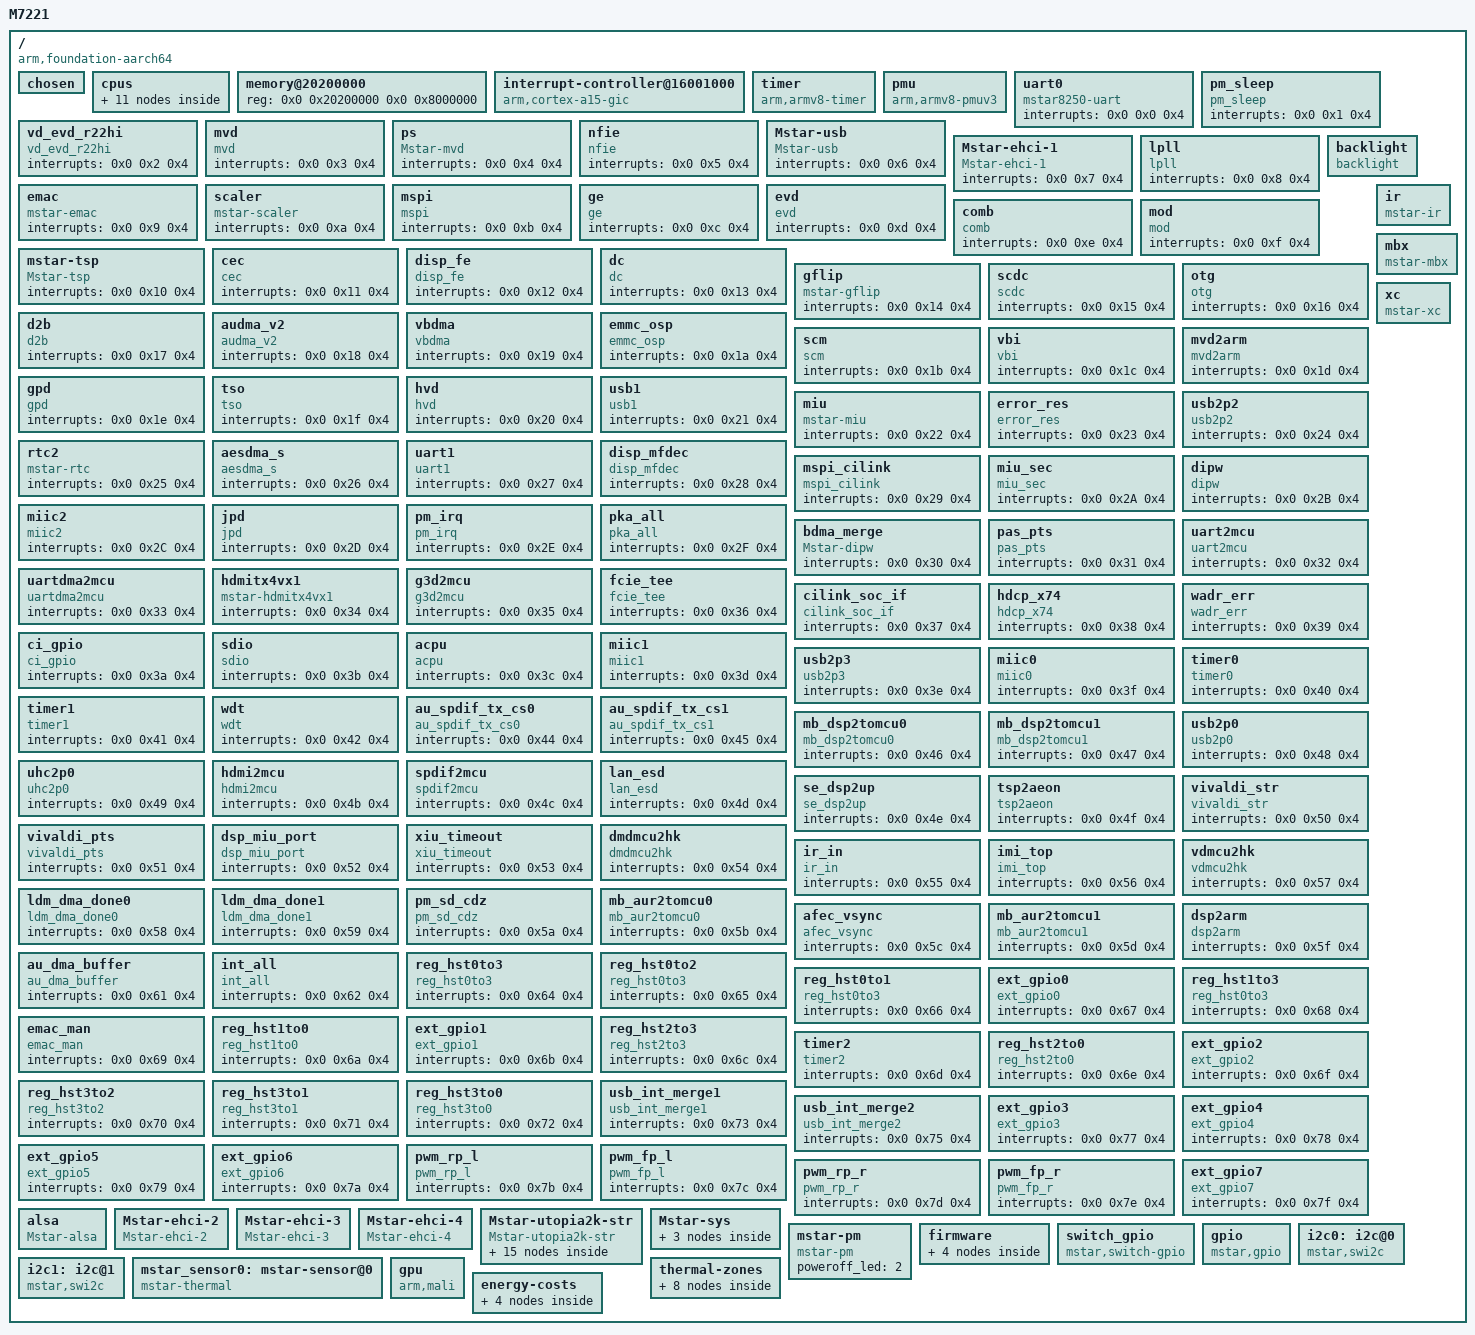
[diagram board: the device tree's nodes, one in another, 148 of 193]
#include <dt-bindings/interrupt-controller/arm-gic.h>
#include <dt-bindings/interrupt-controller/irq.h>
#include <dt-bindings/thermal/thermal.h>

/dts-v1/;

/ {
	model = "M7221";
	compatible = "arm,foundation-aarch64", "arm,m7221";
	interrupt-parent = <0x1>;
	#address-cells = <0x2>;
	#size-cells = <0x2>;

	chosen {
		bootargs = "console=ttyS0,115200 androidboot.console=ttyS0 root=/dev/ram rw rootwait init=/init CORE_DUMP_PATH=/data/core_dump.%%p.gz KDebug=1 delaylogo=true androidboot.selinux=permissive LX_MEM=0x3D500000 LX_MEM2=0xC0000000,0x1FF00000 EMAC_MEM=0x100000 PM51_ADDR=0x20010000 PM51_LEN=0x10000 CMA0=OTHERS,miu=0,hid=23,sz=0x7000000,st=0x11000000 CMA1=VDEC0,miu=0,hid=20,sz=0x3000000,st=0x18000000 CMA2=XC0,miu=0,hid=22,sz=0x6000000,st=0x1b000000 CMA3=OTHERS2,miu=1,hid=24,sz=0xec00000,st=0x0 CMA4=VDEC1,miu=1,hid=19,sz=0x7000000,st=0xec00000 CMA5=RETURN_ENUM,miu=1,hid=25,sz=0x2400000,st=0x15c00000 BOOTLOGO_IN_MBOOT ENV_VAR_OFFSET=0x0 ENV_VAR_SIZE=0x10000 ENV=EMMC SECURITY=ON";
	};

	cpus {
		#address-cells = <0x2>;
		#size-cells = <0x0>;

		cpu-map {

			cluster0: cluster0 {
				#cooling-cells = <0x2>;

				core0 {
					cpu = <0x2>;
				};
                                
				core1 {
					cpu = <0x3>;
				};
			};
                        
			cluster1: cluster1 {
				#cooling-cells = <0x2>;

				core0 {
					cpu = <0x4>;
				};

				core1 {
					cpu = <0x5>;
				};
			};
                       
		};

		cpu0: cpu@0 {
			compatible = "arm,cortex-a53", "arm,armv8";
			reg = <0x0 0x0>;
			device_type = "cpu";
			enable-method = "mstar-spin-table";
			cpu-release-addr = <0x0 0x100510>;
			linux,phandle = <0x2>;
			phandle = <0x2>;
			sched-energy-costs = <&CPU_COST_1 &CLUSTER_COST_1>;
		};

		cpu1: cpu@1 {
			compatible = "arm,cortex-a53", "arm,armv8";
			reg = <0x0 0x1>;
			device_type = "cpu";
			enable-method = "mstar-spin-table";
			cpu-release-addr = <0x0 0x100510>;
			linux,phandle = <0x3>;
			phandle = <0x3>;
			sched-energy-costs = <&CPU_COST_1 &CLUSTER_COST_1>;
		};

		cpu2: cpu@100 {
			compatible = "arm,cortex-a73", "arm,armv8";
			reg = <0x0 0x100>;
			device_type = "cpu";
			enable-method = "mstar-spin-table";
			cpu-release-addr = <0x0 0x100510>;
			linux,phandle = <0x4>;
			phandle = <0x4>;
			sched-energy-costs = <&CPU_COST_0 &CLUSTER_COST_0>;
		};

		cpu3: cpu@101 {
			compatible = "arm,cortex-a73", "arm,armv8";
			reg = <0x0 0x101>;
			device_type = "cpu";
			enable-method = "mstar-spin-table";
			cpu-release-addr = <0x0 0x100510>;
			linux,phandle = <0x5>;
			phandle = <0x5>;
			sched-energy-costs = <&CPU_COST_0 &CLUSTER_COST_0>;
		};
	};

	memory@20200000 {
		device_type = "memory";
		reg = <0x0 0x20200000 0x0 0x8000000>;
	};

	interrupt-controller@16001000 {
		compatible = "arm,cortex-a15-gic", "arm,cortex-a9-gic";
		#interrupt-cells = <0x3>;
		#address-cells = <0x0>;
		interrupt-controller;
		reg = <0x0 0x16001000 0x0 0x1000 0x0 0x16002000 0x0 0x4000>;
		interrupts = <0x1 0x9 0xf04>;
		linux,phandle = <0x1>;
		phandle = <0x1>;
	};

	timer {
		compatible = "arm,armv8-timer";
		interrupts = <0x1 0xd 0xff01 0x1 0xe 0xff01 0x1 0xb 0xff01 0x1 0xa 0xff01>;
		clock-frequency = <0xb71b00>;
	};

	pmu {
		compatible = "arm,armv8-pmuv3";
		interrupts = <0x0 142 0x4>,<0x0 143 0x4>,<0x0 146 0x4>,<0x0 147 0x4>;
		interrupt-affinity = <&cpu0>,<&cpu1>,<&cpu2>,<&cpu3>;
	};

	uart0 {
		compatible = "mstar8250-uart";
		interrupts = <0x0 0x0 0x4>;
	};

	pm_sleep {
		compatible = "pm_sleep";
		interrupts = <0x0 0x1 0x4>;
	};

	vd_evd_r22hi {
		compatible = "vd_evd_r22hi";
		interrupts = <0x0 0x2 0x4>;
	};

	mvd {
		compatible = "mvd";
		interrupts = <0x0 0x3 0x4>;
	};

	ps {
		compatible = "Mstar-mvd";
		interrupts = <0x0 0x4 0x4>;
	};

	nfie {
		compatible = "nfie";
		interrupts = <0x0 0x5 0x4>;
	};

	Mstar-usb {
		compatible = "Mstar-usb";
		interrupts = <0x0 0x6 0x4>;
	};

	Mstar-ehci-1 {
		compatible = "Mstar-ehci-1";
		interrupts = <0x0 0x7 0x4>;
	};

	lpll {
		compatible = "lpll";
		interrupts = <0x0 0x8 0x4>;
	};

	emac {
		compatible = "mstar-emac";
		interrupts = <0x0 0x9 0x4>;
	};

	scaler {
		compatible = "mstar-scaler";
		interrupts = <0x0 0xa 0x4>;
	};

	mspi {
		compatible = "mspi";
		interrupts = <0x0 0xb 0x4>;
	};

	ge {
		compatible = "ge";
		interrupts = <0x0 0xc 0x4>;
	};

	evd   {
		compatible = "evd";
		interrupts = <0x0 0xd 0x4>;
	};

	comb {
		compatible = "comb";
		interrupts = <0x0 0xe 0x4>;
	};

	mod {
		compatible = "mod";
		interrupts = <0x0 0xf 0x4>;
	};

	mstar-tsp {
		compatible = "Mstar-tsp";
		interrupts = <0x0 0x10 0x4>;
	};

	cec {
		compatible = "cec";
		interrupts = <0x0 0x11 0x4>;
	};

	disp_fe {
		compatible = "disp_fe";
		interrupts = <0x0 0x12 0x4>;
	};

	dc {
		compatible = "dc";
		interrupts = <0x0 0x13 0x4>;
	};

    backlight {
        compatible = "backlight";
        brightness-levels = <0 255>;
        default-brightness-level = <1>;
        bl_ctrl = <5>;
    };

	gflip {
		compatible = "mstar-gflip";
		interrupts = <0x0 0x14 0x4>;
	};

	scdc {
		compatible = "scdc";
		interrupts = <0x0 0x15 0x4>;
	};

	otg {
		compatible = "otg";
		interrupts = <0x0 0x16 0x4>;
	};

	d2b {
		compatible = "d2b";
		interrupts = <0x0 0x17 0x4>;
	};

	audma_v2 {
		compatible = "audma_v2";
		interrupts = <0x0 0x18 0x4>;
	};

	vbdma {
		compatible = "vbdma";
		interrupts = <0x0 0x19 0x4>;
	};

	emmc_osp {
		compatible = "emmc_osp";
		interrupts = <0x0 0x1a 0x4>;
	};

	scm {
		compatible = "scm";
		interrupts = <0x0 0x1b 0x4>;
	};

	vbi {
		compatible = "vbi";
		interrupts = <0x0 0x1c 0x4>;
	};

	mvd2arm {
		compatible = "mvd2arm";
		interrupts = <0x0 0x1d 0x4>;
	};

	gpd {
		compatible = "gpd";
		interrupts = <0x0 0x1e 0x4>;
	};

	tso {
		compatible = "tso";
		interrupts = <0x0 0x1f 0x4>;
	};

	hvd {
		compatible = "hvd";
		interrupts = <0x0 0x20 0x4>;
	};

	usb1 {
		compatible = "usb1";
		interrupts = <0x0 0x21 0x4>;
	};

	miu {
		compatible = "mstar-miu";
		interrupts = <0x0 0x22 0x4>;
	};

	error_res {
		compatible = "error_res";
		interrupts = <0x0 0x23 0x4>;
	};

	usb2p2 {
		compatible = "usb2p2";
		interrupts = <0x0 0x24 0x4>;
	};

	rtc2 {
		compatible = "mstar-rtc";
		interrupts = <0x0 0x25 0x4>;
	};

	aesdma_s {
		compatible = "aesdma_s";
		interrupts = <0x0 0x26 0x4>;
	};

	uart1 {
		compatible = "uart1";
		interrupts = <0x0 0x27 0x4>;
	};

	disp_mfdec {
		compatible = "disp_mfdec";
		interrupts = <0x0 0x28 0x4>;
	};

	mspi_cilink {
		compatible = "mspi_cilink";
		interrupts = <0x0 0x29 0x4>;
	};

	miu_sec {
		compatible = "miu_sec";
		interrupts = <0x0 0x2A 0x4>;
	};

	dipw {
		compatible = "dipw";
		interrupts = <0x0 0x2B 0x4>;
	};

	miic2 {
		compatible = "miic2";
		interrupts = <0x0 0x2C 0x4>;
	};

	jpd {
		compatible = "jpd";
		interrupts = <0x0 0x2D 0x4>;
	};

	pm_irq {
		compatible = "pm_irq";
		interrupts = <0x0 0x2E 0x4>;
	};

	pka_all {
		compatible = "pka_all";
		interrupts = <0x0 0x2F 0x4>;
	};

	bdma_merge {
		compatible = "Mstar-dipw";
		interrupts = <0x0 0x30 0x4>;
	};

	pas_pts {
		compatible = "pas_pts";
		interrupts = <0x0 0x31 0x4>;
	};

	uart2mcu {
		compatible = "uart2mcu";
		interrupts = <0x0 0x32 0x4>;
	};

	uartdma2mcu {
		compatible = "uartdma2mcu";
		interrupts = <0x0 0x33 0x4>;
	};

	hdmitx4vx1 {
		compatible = "mstar-hdmitx4vx1";
		interrupts = <0x0 0x34 0x4>;
	};

	g3d2mcu {
		compatible = "g3d2mcu";
		interrupts = <0x0 0x35 0x4>;
	};

	fcie_tee {
		compatible = "fcie_tee";
		interrupts = <0x0 0x36 0x4>;
	};

	cilink_soc_if {
		compatible = "cilink_soc_if";
		interrupts = <0x0 0x37 0x4>;
	};

	hdcp_x74 {
		compatible = "hdcp_x74 ";
		interrupts = <0x0 0x38 0x4>;
	};

	wadr_err {
		compatible = "wadr_err";
		interrupts = <0x0 0x39 0x4>;
	};

	ci_gpio {
		compatible = "ci_gpio";
		interrupts = <0x0 0x3a 0x4>;
	};

	sdio {
		compatible = "sdio";
		interrupts = <0x0 0x3b 0x4>;
	};

	acpu {
		compatible = "acpu";
		interrupts = <0x0 0x3c 0x4>;
	};

	miic1 {
		compatible = "miic1";
		interrupts = <0x0 0x3d 0x4>;
	};

	usb2p3 {
		compatible = "usb2p3";
		interrupts = <0x0 0x3e 0x4>;
	};

	miic0 {
		compatible = "miic0";
		interrupts = <0x0 0x3f 0x4>;
	};

	timer0{
		compatible = "timer0";
		interrupts = <0x0 0x40 0x4>;
	};

	timer1{
		compatible = "timer1";
		interrupts = <0x0 0x41 0x4>;
	};

	wdt {
		compatible = "wdt";
		interrupts = <0x0 0x42 0x4>;
	};

	au_spdif_tx_cs0 {
		compatible = "au_spdif_tx_cs0";
		interrupts = <0x0 0x44 0x4>;
	};

	au_spdif_tx_cs1 {
		compatible = "au_spdif_tx_cs1";
		interrupts = <0x0 0x45 0x4>;
	};

	mb_dsp2tomcu0 {
		compatible = "mb_dsp2tomcu0";
		interrupts = <0x0 0x46 0x4>;
	};

	mb_dsp2tomcu1 {
		compatible = "mb_dsp2tomcu1";
		interrupts = <0x0 0x47 0x4>;
	};

	usb2p0 {
		compatible = "usb2p0";
		interrupts = <0x0 0x48 0x4>;
	};

	uhc2p0 {
		compatible = "uhc2p0";
		interrupts = <0x0 0x49 0x4>;
	};

	hdmi2mcu {
		compatible = "hdmi2mcu";
		interrupts = <0x0 0x4b 0x4>;
	};

	spdif2mcu {
		compatible = "spdif2mcu";
		interrupts = <0x0 0x4c 0x4>;
	};

	lan_esd {
		compatible = "lan_esd";
		interrupts = <0x0 0x4d 0x4>;
	};

	se_dsp2up {
		compatible = "se_dsp2up";
		interrupts = <0x0 0x4e 0x4>;
	};

	tsp2aeon {
		compatible = "tsp2aeon";
		interrupts = <0x0 0x4f 0x4>;
	};

	vivaldi_str {
		compatible = "vivaldi_str";
		interrupts = <0x0 0x50 0x4>;
	};

	vivaldi_pts {
		compatible = "vivaldi_pts";
		interrupts = <0x0 0x51 0x4>;
	};

	dsp_miu_port {
		compatible = "dsp_miu_port";
		interrupts = <0x0 0x52 0x4>;
	};

	xiu_timeout {
		compatible = "xiu_timeout";
		interrupts = <0x0 0x53 0x4>;
	};

	dmdmcu2hk {
		compatible = "dmdmcu2hk";
		interrupts = <0x0 0x54 0x4>;
	};

	ir_in {
		compatible = "ir_in";
		interrupts = <0x0 0x55 0x4>;
	};

	imi_top {
		compatible = "imi_top";
		interrupts = <0x0 0x56 0x4>;
	};

	vdmcu2hk {
		compatible = "vdmcu2hk";
		interrupts = <0x0 0x57 0x4>;
	};

	ldm_dma_done0 {
		compatible = "ldm_dma_done0";
		interrupts = <0x0 0x58 0x4>;
	};

	ldm_dma_done1 {
		compatible = "ldm_dma_done1";
		interrupts = <0x0 0x59 0x4>;
	};

	pm_sd_cdz {
		compatible = "pm_sd_cdz";
		interrupts = <0x0 0x5a 0x4>;
	};

	mb_aur2tomcu0 {
		compatible = "mb_aur2tomcu0";
		interrupts = <0x0 0x5b 0x4>;
	};

	afec_vsync {
		compatible = "afec_vsync";
		interrupts = <0x0 0x5c 0x4>;
	};

	mb_aur2tomcu1 {
		compatible = "mb_aur2tomcu1";
		interrupts = <0x0 0x5d 0x4>;
	};

	dsp2arm {
		compatible = "dsp2arm";
		interrupts = <0x0 0x5f 0x4>;
	};

	au_dma_buffer {
		compatible = "au_dma_buffer";
		interrupts = <0x0 0x61 0x4>;
	};

	int_all {
		compatible = "int_all";
		interrupts = <0x0 0x62 0x4>;
	};

	reg_hst0to3 {
		compatible = "reg_hst0to3";
		interrupts = <0x0 0x64 0x4>;
	};

	reg_hst0to2 {
		compatible = "reg_hst0to3";
		interrupts = <0x0 0x65 0x4>;
	};

	reg_hst0to1 {
		compatible = "reg_hst0to3";
		interrupts = <0x0 0x66 0x4>;
	};

	ext_gpio0 {
		compatible = "ext_gpio0";
		interrupts = <0x0 0x67 0x4>;
	};

	reg_hst1to3 {
		compatible = "reg_hst0to3";
		interrupts = <0x0 0x68 0x4>;
	};

	emac_man {
		compatible = "emac_man";
		interrupts = <0x0 0x69 0x4>;
	};

	reg_hst1to0 {
		compatible = "reg_hst1to0";
		interrupts = <0x0 0x6a 0x4>;
	};

	ext_gpio1 {
		compatible = "ext_gpio1";
		interrupts = <0x0 0x6b 0x4>;
	};

	reg_hst2to3 {
		compatible = "reg_hst2to3";
		interrupts = <0x0 0x6c 0x4>;
	};

	timer2 {
		compatible = "timer2";
		interrupts = <0x0 0x6d 0x4>;
	};

	reg_hst2to0 {
		compatible = "reg_hst2to0";
		interrupts = <0x0 0x6e 0x4>;
	};

	ext_gpio2 {
		compatible = "ext_gpio2";
		interrupts = <0x0 0x6f 0x4>;
	};

	reg_hst3to2 {
		compatible = "reg_hst3to2";
		interrupts = <0x0 0x70 0x4>;
	};

	reg_hst3to1 {
		compatible = "reg_hst3to1";
		interrupts = <0x0 0x71 0x4>;
	};

	reg_hst3to0 {
		compatible = "reg_hst3to0";
		interrupts = <0x0 0x72 0x4>;
	};

	usb_int_merge1 {
		compatible = "usb_int_merge1";
		interrupts = <0x0 0x73 0x4>;
	};

	usb_int_merge2 {
		compatible = "usb_int_merge2";
		interrupts = <0x0 0x75 0x4>;
	};

	ext_gpio3 {
		compatible = "ext_gpio3";
		interrupts = <0x0 0x77 0x4>;
	};

	ext_gpio4 {
		compatible = "ext_gpio4";
		interrupts = <0x0 0x78 0x4>;
	};

	ext_gpio5 {
		compatible = "ext_gpio5";
		interrupts = <0x0 0x79 0x4>;
	};

	ext_gpio6 {
		compatible = "ext_gpio6";
		interrupts = <0x0 0x7a 0x4>;
	};

	pwm_rp_l {
		compatible = "pwm_rp_l";
		interrupts = <0x0 0x7b 0x4>;
	};

	pwm_fp_l {
		compatible = "pwm_fp_l";
		interrupts = <0x0 0x7c 0x4>;
	};

	pwm_rp_r {
		compatible = "pwm_rp_r";
		interrupts = <0x0 0x7d 0x4>;
	};

	pwm_fp_r {
		compatible = "pwm_fp_r";
		interrupts = <0x0 0x7e 0x4>;
	};

	ext_gpio7 {
		compatible = "ext_gpio7";
		interrupts = <0x0 0x7f 0x4>;
	};

	ir {
		compatible = "mstar-ir";
	};

	mbx {
		compatible = "mstar-mbx";
	};

	xc {
		compatible = "mstar-xc";
	};

	alsa {
		compatible = "Mstar-alsa";
	};

	Mstar-ehci-2 {
		compatible = "Mstar-ehci-2";
	};

	Mstar-ehci-3 {
		compatible = "Mstar-ehci-3";
	};

	Mstar-ehci-4 {
		compatible = "Mstar-ehci-4";
	};

	Mstar-utopia2k-str {
		compatible = "Mstar-utopia2k-str";
		mhl {
		  resume {
		    stage0 {
		      pre-condition = "hdmi_rx";
		    };
		  };
		};
		hdmi_rx {
		  resume {
		    stage0 {
		      post-condition = "hdmi_rx";
		    };
		  };
		};
		avd {
		  resume {
		    stage0 {
		      pre-condition = "vif";
		    };
		  };
		};
		vif {
		  resume {
		    stage0 {
		      post-condition = "vif";
		    };
		  };
		};
        miu {
          resume {
            stage0 {
              post-condition = "miu";
            };
          };
        };
	};

        Mstar-sys {
                firmware {
                        audio {
                                path = "/vendor/lib/utopia/";
                        };
                        vdec {
                                path = "/vendor/lib/utopia/";
                        };
                };
        };

	mstar-pm {
		compatible = "mstar-pm";
                poweroff_led = /bits/ 8 <2>;
	};

	firmware {
		android {
			compatible = "android,firmware";
			hardware ="m7221";
			revision ="1234";
			Serial   ="0000000000000000";
			Processor ="AArch64 Processor rev 3 (aarch64)";
			serialno ="123456789";
			mode ="123456789";
			baseband ="123456789";
			bootloader ="123456789";
			fstab {
				compatible = "android,fstab";
				system {
					compatible = "android,system";
					dev = "/dev/block/platform/mstar_mci.0/by-name/system";
					type = "ext4";
					mnt_flags = "ro";
					fsmgr_flags = "wait";
				};
				vendor {
					compatible = "android,system";
					dev = "/dev/block/platform/mstar_mci.0/by-name/vendor";
					type = "ext4";
					mnt_flags = "ro";
					fsmgr_flags = "wait";
				};
			};
		};
	};

	switch_gpio {
		compatible = "mstar,switch-gpio";
		switch-name = "h2w";
		switch-gpio = <999>;
		switch-inverse = <0>;
	};

	gpio: gpio{
		compatible = "mstar,gpio";
		gpio-controller;
		#gpio-cells = <1>;
		interrupt-controller;
		#interrupt-cells = <2>; /* cell name GPIO_PAD, trigger-type*/
	};

	/* example of consume a gpio pin with mapped irq
	foo{
		interrupt-parent = <&gpio>;
		interrupts = <0 LEVEL_HIGH>;
	}
	*/
    i2c0: i2c@0 {
        compatible = "mstar,swi2c";
        bus-index = <0>;
        sda-gpio = <63>;
        scl-gpio = <62>;
        speed-khz = <100>;
        def-delay = <100>;
        retries = <5>;
        status = "okay";
        iic-mode = <1>;
        hw-port = <0>;
        pad-mux = <1>;
    };
    i2c1: i2c@1 {
        compatible = "mstar,swi2c";
        bus-index = <1>;
        sda-gpio = <98>;
        scl-gpio = <97>;
        speed-khz = <100>;
        def-delay = <100>;
        retries = <5>;
        status = "okay";
        iic-mode = <0>;
        hw-port = <0>;
        pad-mux = <0>;
    };
	mstar_sensor0: mstar-sensor@0 {
		compatible = "mstar-thermal";
		#thermal-sensor-cells = <1>;
	};
        gpu: gpu {
                compatible = "arm,mali";
                #cooling-cells = <2>; /* min followed by max */
        };
	thermal-zones {
		mstar_thermal: mstar-thermal {
			polling-delay = <1000>;
			polling-delay-passive = <100>;
			sustainable-power = <6000>;

			thermal-sensors = <&mstar_sensor0 0>;

			trips {
				threshold: trip-point@0 {
					temperature = <120000>;
					hysteresis = <1000>;
					type = "passive";
				};
				target: trip-point@1 {
					temperature = <130000>;
					hysteresis = <1000>;
					type = "passive";
				};
			};

			cooling-maps {
			        map0 {
				     trip = <&target>;
				     contribution = <2048>;
				     cooling-device = <&cluster0 THERMAL_NO_LIMIT THERMAL_NO_LIMIT>;
				};
				map1 {
				     trip = <&target>;
				     contribution = <1024>;
				     cooling-device = <&cluster1 THERMAL_NO_LIMIT THERMAL_NO_LIMIT>;
				};
				map2 {
				     trip = <&target>;
				     contribution = <1024>;
				     cooling-device = <&gpu 0 4>;
				};

			};
		};
	};
    energy-costs {
        CPU_COST_0: core-cost0 {
            busy-cost-data = <
                804 657
                877 769
                951 890
                1024 1022
            >;
            idle-cost-data = <
                15
                0
            >;
        };
        CPU_COST_1: core-cost1 {
            busy-cost-data = <
                493 144
                537 176
                582 213
                627 253
            >;
            idle-cost-data = <
                6
                0
            >;
        };
        CLUSTER_COST_0: cluster-cost0 {
            busy-cost-data = <
                804 68
                877 78
                951 89
                1024 100
            >;
            idle-cost-data = <
                65
                24
            >;
        };
        CLUSTER_COST_1: cluster-cost1 {
            busy-cost-data = <
                493 142
                537 174
                582 210
                627 250
            >;
            idle-cost-data = <
                56
                17
            >;
        };
    };
};
